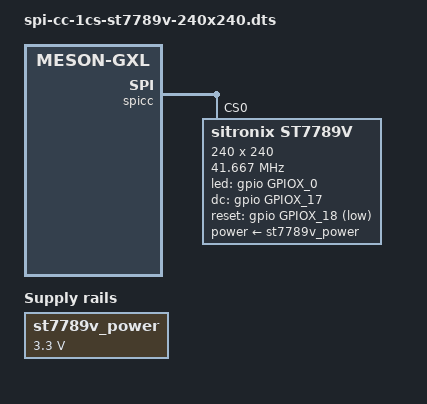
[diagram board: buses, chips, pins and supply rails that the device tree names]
// SPDX-License-Identifier: (GPL-2.0-or-later OR MIT)
/*
 * Copyright (c) 2022 Da Xue
 * Author: Da Xue <da@libre.computer>
 */
/*
 * Summary: Power-supply: HAT VCC is hardwired/variable per module, so a dummy
 *
 * Pins (Header.Pin  Name  Pad  Ref — cross-ref gpio.map):
 *   7J1.22   GPIOX_0       A2      WIFI_SD_D0
 *   7J1.29   GPIOX_17      B5      BT_EN
 *   7J1.31   GPIOX_18      B7      BT_WAKE_HOST
 *
 * Requires: spi-cc-1cs
 *
 * Notes:
 * Display stack: mixed. Shared SPI/GPIO fields serve tinydrm when the
 * compatible matches a DRM driver; properties tagged "fbtft/legacy" are only
 * for staging fbtft (CONFIG_FB_TFT_*).
 * regulator-fixed (no GPIO) satisfies panel-sitronix-st7789v + schema.
 * Enable/disable is a software refcount only — does not gate real power.
 */
/dts-v1/;
/plugin/;

#include <dt-bindings/gpio/gpio.h>
#include <dt-bindings/gpio/meson-gxl-gpio.h>

/ {
	compatible = "libre-computer,aml-s905x-cc",
		     "libretech,aml-s905x-cc",
		     "libre-computer,aml-s905x-cc-v2",
		     "libretech,aml-s905x-cc-v2",
		     "amlogic,s905x",
		     "amlogic,meson-gxl";

	fragment@0 {
		target-path = "/";

		__overlay__ {
			st7789v_power: regulator-st7789v-power {
				compatible = "regulator-fixed";
				regulator-name = "st7789v-power";
				regulator-min-microvolt = <3300000>;
				regulator-max-microvolt = <3300000>;
			};
		};
	};

	fragment@1 {
		target = <&spicc>;

		__overlay__ {
			st7789v@0 {
				compatible = "sitronix,st7789v";
				reg = <0>;
				power-supply = <&st7789v_power>;
				led-gpios = <&gpio GPIOX_0 GPIO_ACTIVE_HIGH>; /* fbtft/legacy */
				dc-gpios = <&gpio GPIOX_17 GPIO_ACTIVE_HIGH>;
				reset-gpios = <&gpio GPIOX_18 GPIO_ACTIVE_LOW>;
				height = <240>; /* fbtft/legacy */
				width = <240>; /* fbtft/legacy */
				buswidth = <16>; /* fbtft/legacy */
				spi-cpol;
				spi-cpha;
				spi-max-frequency = <41666666>;
				status = "okay";
			};
		};
	};
};
